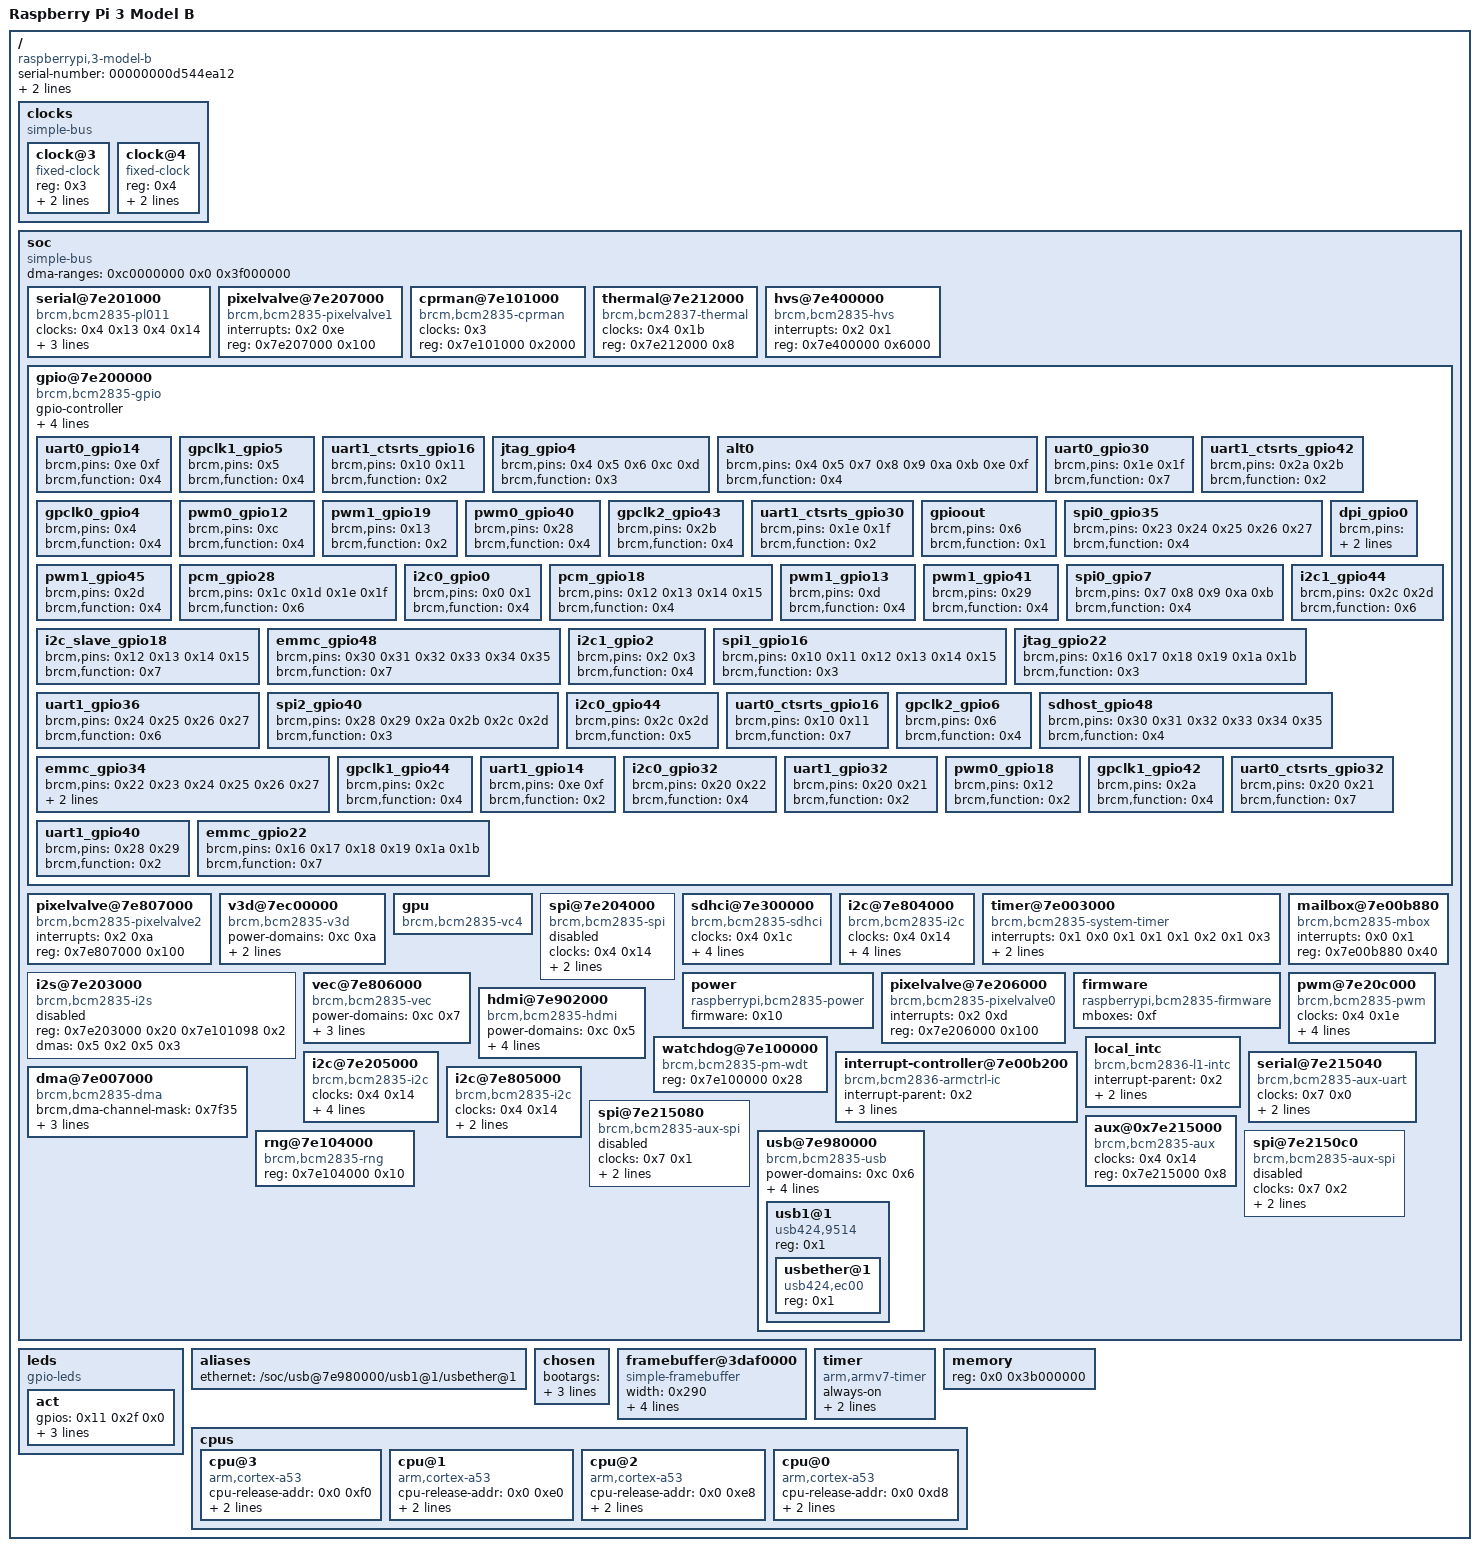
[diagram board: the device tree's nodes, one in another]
/dts-v1/;

/ {
	compatible = "raspberrypi,3-model-b", "brcm,bcm2837";
	serial-number = "00000000d544ea12";
	model = "Raspberry Pi 3 Model B";
	interrupt-parent = <0x1>;
	#address-cells = <0x1>;
	#size-cells = <0x1>;

	clocks {
		compatible = "simple-bus";
		#address-cells = <0x1>;
		#size-cells = <0x0>;

		clock@3 {
			compatible = "fixed-clock";
			#clock-cells = <0x0>;
			phandle = <0x3>;
			reg = <0x3>;
			clock-output-names = "osc";
			clock-frequency = <0x124f800>;
			linux,phandle = <0x3>;
		};

		clock@4 {
			compatible = "fixed-clock";
			#clock-cells = <0x0>;
			phandle = <0xe>;
			reg = <0x4>;
			clock-output-names = "otg";
			clock-frequency = <0x1c9c3800>;
			linux,phandle = <0xe>;
		};
	};

	soc {
		compatible = "simple-bus";
		ranges = <0x7e000000 0x3f000000 0x1000000 0x40000000 0x40000000 0x1000>;
		#address-cells = <0x1>;
		#size-cells = <0x1>;
		dma-ranges = <0xc0000000 0x0 0x3f000000>;

		serial@7e201000 {
			compatible = "brcm,bcm2835-pl011", "arm,pl011", "arm,primecell";
			clocks = <0x4 0x13 0x4 0x14>;
			clock-names = "uartclk", "apb_pclk";
			interrupts = <0x2 0x19>;
			arm,primecell-periphid = <0x241011>;
			reg = <0x7e201000 0x1000>;
		};

		pixelvalve@7e207000 {
			compatible = "brcm,bcm2835-pixelvalve1";
			interrupts = <0x2 0xe>;
			reg = <0x7e207000 0x100>;
		};

		cprman@7e101000 {
			compatible = "brcm,bcm2835-cprman";
			clocks = <0x3>;
			#clock-cells = <0x1>;
			phandle = <0x4>;
			reg = <0x7e101000 0x2000>;
			linux,phandle = <0x4>;
		};

		thermal@7e212000 {
			compatible = "brcm,bcm2837-thermal";
			clocks = <0x4 0x1b>;
			status = "okay";
			reg = <0x7e212000 0x8>;
		};

		hvs@7e400000 {
			compatible = "brcm,bcm2835-hvs";
			interrupts = <0x2 0x1>;
			reg = <0x7e400000 0x6000>;
		};

		gpio@7e200000 {
			compatible = "brcm,bcm2835-gpio";
			gpio-controller;
			#interrupt-cells = <0x2>;
			interrupts = <0x2 0x11 0x2 0x12 0x2 0x13 0x2 0x14>;
			phandle = <0x11>;
			reg = <0x7e200000 0xb4>;
			#gpio-cells = <0x2>;
			linux,phandle = <0x11>;
			pinctrl-names = "default";
			interrupt-controller;

			uart0_gpio14 {
				brcm,pins = <0xe 0xf>;
				brcm,function = <0x4>;
			};

			gpclk1_gpio5 {
				brcm,pins = <0x5>;
				brcm,function = <0x4>;
			};

			uart1_ctsrts_gpio16 {
				brcm,pins = <0x10 0x11>;
				brcm,function = <0x2>;
			};

			jtag_gpio4 {
				brcm,pins = <0x4 0x5 0x6 0xc 0xd>;
				brcm,function = <0x3>;
			};

			alt0 {
				brcm,pins = <0x4 0x5 0x7 0x8 0x9 0xa 0xb 0xe 0xf>;
				brcm,function = <0x4>;
			};

			uart0_gpio30 {
				brcm,pins = <0x1e 0x1f>;
				brcm,function = <0x7>;
			};

			uart1_ctsrts_gpio42 {
				brcm,pins = <0x2a 0x2b>;
				brcm,function = <0x2>;
			};

			gpclk0_gpio4 {
				brcm,pins = <0x4>;
				brcm,function = <0x4>;
			};

			pwm0_gpio12 {
				brcm,pins = <0xc>;
				brcm,function = <0x4>;
			};

			pwm1_gpio19 {
				brcm,pins = <0x13>;
				brcm,function = <0x2>;
			};

			pwm0_gpio40 {
				brcm,pins = <0x28>;
				phandle = <0x8>;
				brcm,function = <0x4>;
				linux,phandle = <0x8>;
			};

			gpclk2_gpio43 {
				brcm,pins = <0x2b>;
				brcm,function = <0x4>;
			};

			uart1_ctsrts_gpio30 {
				brcm,pins = <0x1e 0x1f>;
				brcm,function = <0x2>;
			};

			gpioout {
				brcm,pins = <0x6>;
				brcm,function = <0x1>;
			};

			spi0_gpio35 {
				brcm,pins = <0x23 0x24 0x25 0x26 0x27>;
				brcm,function = <0x4>;
			};

			pwm1_gpio45 {
				brcm,pins = <0x2d>;
				phandle = <0x9>;
				brcm,function = <0x4>;
				linux,phandle = <0x9>;
			};

			pcm_gpio28 {
				brcm,pins = <0x1c 0x1d 0x1e 0x1f>;
				brcm,function = <0x6>;
			};

			dpi_gpio0 {
				brcm,pins = <0x0 0x1 0x2 0x3 0x4 0x5 0x6 0x7 0x8 0x9 0xa 0xb 0xc 0xd 0xe 0xf 0x10 0x11 0x12 0x13 0x14 0x15 0x16 0x17 0x18 0x19 0x1a 0x1b>;
				brcm,function = <0x6>;
			};

			i2c0_gpio0 {
				brcm,pins = <0x0 0x1>;
				phandle = <0x6>;
				brcm,function = <0x4>;
				linux,phandle = <0x6>;
			};

			pcm_gpio18 {
				brcm,pins = <0x12 0x13 0x14 0x15>;
				brcm,function = <0x4>;
			};

			pwm1_gpio13 {
				brcm,pins = <0xd>;
				brcm,function = <0x4>;
			};

			pwm1_gpio41 {
				brcm,pins = <0x29>;
				brcm,function = <0x4>;
			};

			spi0_gpio7 {
				brcm,pins = <0x7 0x8 0x9 0xa 0xb>;
				brcm,function = <0x4>;
			};

			i2c1_gpio44 {
				brcm,pins = <0x2c 0x2d>;
				brcm,function = <0x6>;
			};

			i2c_slave_gpio18 {
				brcm,pins = <0x12 0x13 0x14 0x15>;
				brcm,function = <0x7>;
			};

			emmc_gpio48 {
				brcm,pins = <0x30 0x31 0x32 0x33 0x34 0x35>;
				phandle = <0xa>;
				brcm,function = <0x7>;
				linux,phandle = <0xa>;
			};

			i2c1_gpio2 {
				brcm,pins = <0x2 0x3>;
				phandle = <0xb>;
				brcm,function = <0x4>;
				linux,phandle = <0xb>;
			};

			spi1_gpio16 {
				brcm,pins = <0x10 0x11 0x12 0x13 0x14 0x15>;
				brcm,function = <0x3>;
			};

			jtag_gpio22 {
				brcm,pins = <0x16 0x17 0x18 0x19 0x1a 0x1b>;
				brcm,function = <0x3>;
			};

			uart1_gpio36 {
				brcm,pins = <0x24 0x25 0x26 0x27>;
				brcm,function = <0x6>;
			};

			spi2_gpio40 {
				brcm,pins = <0x28 0x29 0x2a 0x2b 0x2c 0x2d>;
				brcm,function = <0x3>;
			};

			i2c0_gpio44 {
				brcm,pins = <0x2c 0x2d>;
				brcm,function = <0x5>;
			};

			uart0_ctsrts_gpio16 {
				brcm,pins = <0x10 0x11>;
				brcm,function = <0x7>;
			};

			gpclk2_gpio6 {
				brcm,pins = <0x6>;
				brcm,function = <0x4>;
			};

			sdhost_gpio48 {
				brcm,pins = <0x30 0x31 0x32 0x33 0x34 0x35>;
				brcm,function = <0x4>;
			};

			emmc_gpio34 {
				brcm,pins = <0x22 0x23 0x24 0x25 0x26 0x27>;
				brcm,pull = <0x0 0x2 0x2 0x2 0x2 0x2>;
				brcm,function = <0x7>;
			};

			gpclk1_gpio44 {
				brcm,pins = <0x2c>;
				brcm,function = <0x4>;
			};

			uart1_gpio14 {
				brcm,pins = <0xe 0xf>;
				brcm,function = <0x2>;
			};

			i2c0_gpio32 {
				brcm,pins = <0x20 0x22>;
				brcm,function = <0x4>;
			};

			uart1_gpio32 {
				brcm,pins = <0x20 0x21>;
				brcm,function = <0x2>;
			};

			pwm0_gpio18 {
				brcm,pins = <0x12>;
				brcm,function = <0x2>;
			};

			gpclk1_gpio42 {
				brcm,pins = <0x2a>;
				brcm,function = <0x4>;
			};

			uart0_ctsrts_gpio32 {
				brcm,pins = <0x20 0x21>;
				brcm,function = <0x7>;
			};

			uart1_gpio40 {
				brcm,pins = <0x28 0x29>;
				brcm,function = <0x2>;
			};

			emmc_gpio22 {
				brcm,pins = <0x16 0x17 0x18 0x19 0x1a 0x1b>;
				brcm,function = <0x7>;
			};
		};

		pixelvalve@7e807000 {
			compatible = "brcm,bcm2835-pixelvalve2";
			interrupts = <0x2 0xa>;
			reg = <0x7e807000 0x100>;
		};

		v3d@7ec00000 {
			power-domains = <0xc 0xa>;
			compatible = "brcm,bcm2835-v3d";
			interrupts = <0x1 0xa>;
			reg = <0x7ec00000 0x1000>;
		};

		gpu {
			compatible = "brcm,bcm2835-vc4";
		};

		spi@7e204000 {
			compatible = "brcm,bcm2835-spi";
			clocks = <0x4 0x14>;
			status = "disabled";
			#address-cells = <0x1>;
			interrupts = <0x2 0x16>;
			#size-cells = <0x0>;
			reg = <0x7e204000 0x1000>;
		};

		sdhci@7e300000 {
			compatible = "brcm,bcm2835-sdhci";
			clocks = <0x4 0x1c>;
			status = "okay";
			interrupts = <0x2 0x1e>;
			bus-width = <0x4>;
			reg = <0x7e300000 0x100>;
			pinctrl-0 = <0xa>;
			pinctrl-names = "default";
		};

		i2c@7e804000 {
			compatible = "brcm,bcm2835-i2c";
			clocks = <0x4 0x14>;
			status = "okay";
			#address-cells = <0x1>;
			interrupts = <0x2 0x15>;
			#size-cells = <0x0>;
			reg = <0x7e804000 0x1000>;
			clock-frequency = <0x186a0>;
			pinctrl-0 = <0xb>;
			pinctrl-names = "default";
		};

		timer@7e003000 {
			compatible = "brcm,bcm2835-system-timer";
			interrupts = <0x1 0x0 0x1 0x1 0x1 0x2 0x1 0x3>;
			reg = <0x7e003000 0x1000>;
			clock-frequency = <0xf4240>;
		};

		i2s@7e203000 {
			compatible = "brcm,bcm2835-i2s";
			status = "disabled";
			dma-names = "tx", "rx";
			reg = <0x7e203000 0x20 0x7e101098 0x2>;
			dmas = <0x5 0x2 0x5 0x3>;
		};

		mailbox@7e00b880 {
			compatible = "brcm,bcm2835-mbox";
			#mbox-cells = <0x0>;
			interrupts = <0x0 0x1>;
			phandle = <0xf>;
			reg = <0x7e00b880 0x40>;
			linux,phandle = <0xf>;
		};

		vec@7e806000 {
			power-domains = <0xc 0x7>;
			compatible = "brcm,bcm2835-vec";
			clocks = <0x4 0x18>;
			status = "okay";
			interrupts = <0x2 0x1b>;
			reg = <0x7e806000 0x1000>;
		};

		power {
			compatible = "raspberrypi,bcm2835-power";
			firmware = <0x10>;
			phandle = <0xc>;
			linux,phandle = <0xc>;
			#power-domain-cells = <0x1>;
		};

		pixelvalve@7e206000 {
			compatible = "brcm,bcm2835-pixelvalve0";
			interrupts = <0x2 0xd>;
			reg = <0x7e206000 0x100>;
		};

		firmware {
			compatible = "raspberrypi,bcm2835-firmware";
			mboxes = <0xf>;
			phandle = <0x10>;
			linux,phandle = <0x10>;
		};

		hdmi@7e902000 {
			power-domains = <0xc 0x5>;
			compatible = "brcm,bcm2835-hdmi";
			clocks = <0x4 0x10 0x4 0x19>;
			clock-names = "pixel", "hdmi";
			ddc = <0xd>;
			status = "okay";
			interrupts = <0x2 0x8 0x2 0x9>;
			reg = <0x7e902000 0x600 0x7e808000 0x100>;
		};

		pwm@7e20c000 {
			compatible = "brcm,bcm2835-pwm";
			clocks = <0x4 0x1e>;
			status = "okay";
			assigned-clock-rates = <0x989680>;
			assigned-clocks = <0x4 0x1e>;
			reg = <0x7e20c000 0x28>;
			pinctrl-0 = <0x8 0x9>;
			#pwm-cells = <0x2>;
			pinctrl-names = "default";
		};

		watchdog@7e100000 {
			compatible = "brcm,bcm2835-pm-wdt";
			reg = <0x7e100000 0x28>;
		};

		interrupt-controller@7e00b200 {
			compatible = "brcm,bcm2836-armctrl-ic";
			#interrupt-cells = <0x2>;
			interrupt-parent = <0x2>;
			interrupts = <0x8>;
			phandle = <0x1>;
			reg = <0x7e00b200 0x200>;
			linux,phandle = <0x1>;
			interrupt-controller;
		};

		local_intc {
			compatible = "brcm,bcm2836-l1-intc";
			#interrupt-cells = <0x1>;
			interrupt-parent = <0x2>;
			phandle = <0x2>;
			reg = <0x40000000 0x100>;
			linux,phandle = <0x2>;
			interrupt-controller;
		};

		i2c@7e205000 {
			compatible = "brcm,bcm2835-i2c";
			clocks = <0x4 0x14>;
			status = "okay";
			#address-cells = <0x1>;
			interrupts = <0x2 0x15>;
			#size-cells = <0x0>;
			reg = <0x7e205000 0x1000>;
			clock-frequency = <0x186a0>;
			pinctrl-0 = <0x6>;
			pinctrl-names = "default";
		};

		serial@7e215040 {
			compatible = "brcm,bcm2835-aux-uart";
			clocks = <0x7 0x0>;
			status = "okay";
			interrupts = <0x1 0x1d>;
			reg = <0x7e215040 0x40>;
		};

		dma@7e007000 {
			#dma-cells = <0x1>;
			compatible = "brcm,bcm2835-dma";
			brcm,dma-channel-mask = <0x7f35>;
			interrupts = <0x1 0x10 0x1 0x11 0x1 0x12 0x1 0x13 0x1 0x14 0x1 0x15 0x1 0x16 0x1 0x17 0x1 0x18 0x1 0x19 0x1 0x1a 0x1 0x1b 0x1 0x1b 0x1 0x1b 0x1 0x1b 0x1 0x1c>;
			phandle = <0x5>;
			reg = <0x7e007000 0xf00>;
			linux,phandle = <0x5>;
			interrupt-names = "dma0", "dma1", "dma2", "dma3", "dma4", "dma5", "dma6", "dma7", "dma8", "dma9", "dma10", "dma11", "dma12", "dma13", "dma14", "dma-shared-all";
		};

		i2c@7e805000 {
			compatible = "brcm,bcm2835-i2c";
			clocks = <0x4 0x14>;
			status = "okay";
			#address-cells = <0x1>;
			interrupts = <0x2 0x15>;
			#size-cells = <0x0>;
			phandle = <0xd>;
			reg = <0x7e805000 0x1000>;
			linux,phandle = <0xd>;
		};

		spi@7e215080 {
			compatible = "brcm,bcm2835-aux-spi";
			clocks = <0x7 0x1>;
			status = "disabled";
			#address-cells = <0x1>;
			interrupts = <0x1 0x1d>;
			#size-cells = <0x0>;
			reg = <0x7e215080 0x40>;
		};

		aux@0x7e215000 {
			compatible = "brcm,bcm2835-aux";
			clocks = <0x4 0x14>;
			#clock-cells = <0x1>;
			phandle = <0x7>;
			reg = <0x7e215000 0x8>;
			linux,phandle = <0x7>;
		};

		rng@7e104000 {
			compatible = "brcm,bcm2835-rng";
			reg = <0x7e104000 0x10>;
		};

		usb@7e980000 {
			power-domains = <0xc 0x6>;
			compatible = "brcm,bcm2835-usb";
			clocks = <0xe>;
			clock-names = "otg";
			#address-cells = <0x1>;
			interrupts = <0x1 0x9>;
			#size-cells = <0x0>;
			reg = <0x7e980000 0x10000>;
			dr_mode = "host";

			usb1@1 {
				compatible = "usb424,9514";
				#address-cells = <0x1>;
				#size-cells = <0x0>;
				reg = <0x1>;

				usbether@1 {
					compatible = "usb424,ec00";
					reg = <0x1>;
				};
			};
		};

		spi@7e2150c0 {
			compatible = "brcm,bcm2835-aux-spi";
			clocks = <0x7 0x2>;
			status = "disabled";
			#address-cells = <0x1>;
			interrupts = <0x1 0x1d>;
			#size-cells = <0x0>;
			reg = <0x7e2150c0 0x40>;
		};
	};

	leds {
		compatible = "gpio-leds";

		act {
			gpios = <0x11 0x2f 0x0>;
			label = "ACT";
			default-state = "keep";
			linux,default-trigger = "heartbeat";
		};
	};

	aliases {
		ethernet = "/soc/usb@7e980000/usb1@1/usbether@1";
	};

	chosen {
		bootargs = "console=ttyS0,115200 console=tty0 root=PARTUUID=08d5518c-02 rw rootwait smsc95xx.macaddr=01:02:03:04:05:06";
		linux,initrd-start = ":wP";
		linux,initrd-end = <0x3ab2d71e>;
	};

	framebuffer@3daf0000 {
		compatible = "simple-framebuffer";
		width = <0x290>;
		stride = <0xa40>;
		status = "okay";
		reg = <0x3daf0000 0x10a800>;
		format = "a8r8g8b8";
		height = <0x1a0>;
	};

	timer {
		compatible = "arm,armv7-timer";
		always-on;
		interrupt-parent = <0x2>;
		interrupts = <0x0 0x1 0x3 0x2>;
	};

	memory {
		device_type = "memory";
		reg = <0x0 0x3b000000>;
	};

	cpus {
		#address-cells = <0x1>;
		#size-cells = <0x0>;

		cpu@3 {
			compatible = "arm,cortex-a53";
			cpu-release-addr = <0x0 0xf0>;
			device_type = "cpu";
			enable-method = "spin-table";
			reg = <0x3>;
		};

		cpu@1 {
			compatible = "arm,cortex-a53";
			cpu-release-addr = <0x0 0xe0>;
			device_type = "cpu";
			enable-method = "spin-table";
			reg = <0x1>;
		};

		cpu@2 {
			compatible = "arm,cortex-a53";
			cpu-release-addr = <0x0 0xe8>;
			device_type = "cpu";
			enable-method = "spin-table";
			reg = <0x2>;
		};

		cpu@0 {
			compatible = "arm,cortex-a53";
			cpu-release-addr = <0x0 0xd8>;
			device_type = "cpu";
			enable-method = "spin-table";
			reg = <0x0>;
		};
	};
};
